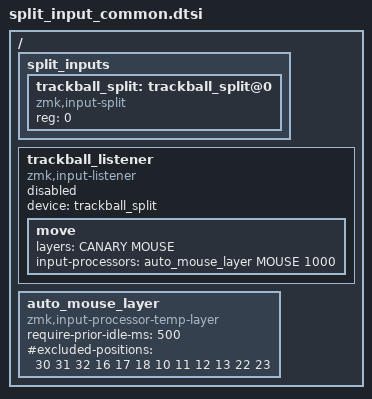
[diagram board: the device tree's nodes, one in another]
#include <input/processors.dtsi>

#define CANARY 0
#define MOUSE 9

/ {
  split_inputs {
    #address-cells = <1>;
    #size-cells = <0>;

    trackball_split: trackball_split@0 {
      compatible = "zmk,input-split";
      reg = <0>;
    };
  };

  trackball_listener: trackball_listener {
    compatible = "zmk,input-listener";
    status = "disabled";
    device = <&trackball_split>;

    move {
      layers = <CANARY MOUSE>;
      input-processors = <&auto_mouse_layer MOUSE 1000>;
    };
  };

  auto_mouse_layer: auto_mouse_layer {
    compatible = "zmk,input-processor-temp-layer";
    #input-processor-cells = <2>;
    require-prior-idle-ms = <500>;
    #excluded-positions = <30 31 32 16 17 18 10 11 12 13 22 23>;
  };
};
